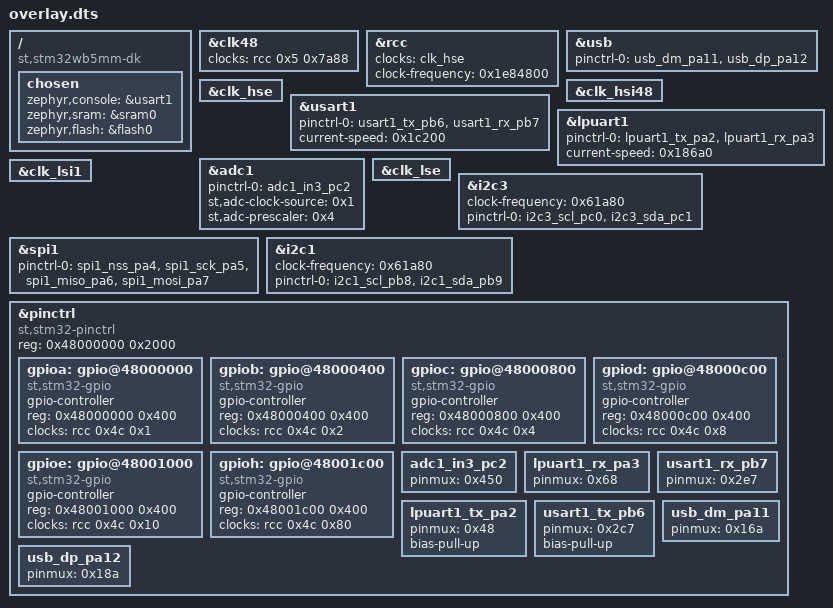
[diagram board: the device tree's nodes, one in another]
/ {
	compatible = "st,stm32wb5mm-dk";
	chosen {
		zephyr,console = &usart1;
		zephyr,sram = &sram0;
		zephyr,flash = &flash0;
	};
};
&clk48{
	clocks = < &rcc 0x5 0x7a88 >;
};
&rcc{
	clocks = < &clk_hse >;
	clock-frequency = < 0x1e84800 >;
};
&usb{
	status = "okay";
	pinctrl-0 = < &usb_dm_pa11 &usb_dp_pa12 >;
	pinctrl-names = "default";
};
&clk_hse{
	status = "okay";
};
&clk_hsi48{
	status = "okay";
};
&usart1{
	status = "okay";
	pinctrl-0 = < &usart1_tx_pb6 &usart1_rx_pb7 >;
	pinctrl-names = "default";
	current-speed = < 0x1c200 >;
};
&lpuart1{
	status = "okay";
	pinctrl-0 = < &lpuart1_tx_pa2 &lpuart1_rx_pa3 >;
	pinctrl-names = "default";
	current-speed = < 0x186a0 >;
};
&adc1{
	status = "okay";
	pinctrl-0 = < &adc1_in3_pc2 >;
	pinctrl-names = "default";
	st,adc-clock-source = < 0x1 >;
	st,adc-prescaler = < 0x4 >;
};
&clk_lse{
	status = "okay";
};
&i2c3{
	clock-frequency = < 0x61a80 >;
	status = "okay";
	pinctrl-0 = < &i2c3_scl_pc0 &i2c3_sda_pc1 >;
	pinctrl-names = "default";
};
&clk_lsi1{
	status = "okay";
};
&spi1{
	status = "okay";
	pinctrl-0 = < &spi1_nss_pa4 &spi1_sck_pa5 &spi1_miso_pa6 &spi1_mosi_pa7 >;
	pinctrl-names = "default";
};
&i2c1{
	clock-frequency = < 0x61a80 >;
	status = "okay";
	pinctrl-0 = < &i2c1_scl_pb8 &i2c1_sda_pb9 >;
	pinctrl-names = "default";
};
&pinctrl{
	compatible = "st,stm32-pinctrl";
	#address-cells = < 0x1 >;
	#size-cells = < 0x1 >;
	reg = < 0x48000000 0x2000 >;
	gpioa: gpio@48000000 {
		compatible = "st,stm32-gpio";
		gpio-controller;
		#gpio-cells = < 0x2 >;
		reg = < 0x48000000 0x400 >;
		clocks = < &rcc 0x4c 0x1 >;
	};
	gpiob: gpio@48000400 {
		compatible = "st,stm32-gpio";
		gpio-controller;
		#gpio-cells = < 0x2 >;
		reg = < 0x48000400 0x400 >;
		clocks = < &rcc 0x4c 0x2 >;
	};
	gpioc: gpio@48000800 {
		compatible = "st,stm32-gpio";
		gpio-controller;
		#gpio-cells = < 0x2 >;
		reg = < 0x48000800 0x400 >;
		clocks = < &rcc 0x4c 0x4 >;
	};
	gpiod: gpio@48000c00 {
		compatible = "st,stm32-gpio";
		gpio-controller;
		#gpio-cells = < 0x2 >;
		reg = < 0x48000c00 0x400 >;
		clocks = < &rcc 0x4c 0x8 >;
	};
	gpioe: gpio@48001000 {
		compatible = "st,stm32-gpio";
		gpio-controller;
		#gpio-cells = < 0x2 >;
		reg = < 0x48001000 0x400 >;
		clocks = < &rcc 0x4c 0x10 >;
	};
	gpioh: gpio@48001c00 {
		compatible = "st,stm32-gpio";
		gpio-controller;
		#gpio-cells = < 0x2 >;
		reg = < 0x48001c00 0x400 >;
		clocks = < &rcc 0x4c 0x80 >;
	};
	adc1_in3_pc2: adc1_in3_pc2 {
		pinmux = < 0x450 >;
	};
	lpuart1_rx_pa3: lpuart1_rx_pa3 {
		pinmux = < 0x68 >;
	};
	usart1_rx_pb7: usart1_rx_pb7 {
		pinmux = < 0x2e7 >;
	};
	lpuart1_tx_pa2: lpuart1_tx_pa2 {
		pinmux = < 0x48 >;
		bias-pull-up;
	};
	usart1_tx_pb6: usart1_tx_pb6 {
		pinmux = < 0x2c7 >;
		bias-pull-up;
	};
	usb_dm_pa11: usb_dm_pa11 {
		pinmux = < 0x16a >;
	};
	usb_dp_pa12: usb_dp_pa12 {
		pinmux = < 0x18a >;
	};
};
